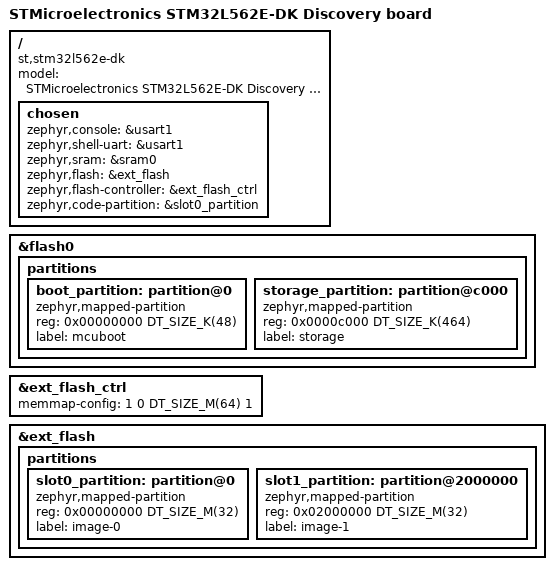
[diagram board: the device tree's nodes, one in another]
/*
 * Copyright (c) 2026 STMicroelectronics
 *
 * SPDX-License-Identifier: Apache-2.0
 */

/dts-v1/;
#include "stm32l562e_dk-common.dtsi"

/ {
	compatible = "st,stm32l562e-dk";
	model = "STMicroelectronics STM32L562E-DK Discovery board";

	chosen {
		zephyr,console = &usart1;
		zephyr,shell-uart = &usart1;
		zephyr,sram = &sram0;
		zephyr,flash = &ext_flash;
		zephyr,flash-controller = &ext_flash_ctrl;
		zephyr,code-partition = &slot0_partition;
	};
};

&flash0 {
	partitions {
		ranges;
		#address-cells = <1>;
		#size-cells = <1>;

		boot_partition: partition@0 {
			compatible = "zephyr,mapped-partition";
			reg = <0x00000000 DT_SIZE_K(48)>;
			label = "mcuboot";
		};

		storage_partition: partition@c000 {
			compatible = "zephyr,mapped-partition";
			reg = <0x0000c000 DT_SIZE_K(464)>;
			label = "storage";
		};
	};
};

&ext_flash_ctrl {
	memmap-config = <1 0 DT_SIZE_M(64) 1>;
};

&ext_flash {
	partitions {
		ranges;
		#address-cells = <1>;
		#size-cells = <1>;

		slot0_partition: partition@0 {
			compatible = "zephyr,mapped-partition";
			reg = <0x00000000 DT_SIZE_M(32)>;
			label = "image-0";
		};

		slot1_partition: partition@2000000 {
			compatible = "zephyr,mapped-partition";
			reg = <0x02000000 DT_SIZE_M(32)>;
			label = "image-1";
		};
	};
};
